# pse84 register map
Vendor: Infineon Technologies; Series: PSE84; File version: 1.0
CPU: CM33 r0p1, little endian, MPU, FPU, VTOR, 3 interrupt priority bits
Registers are 32-bit, read-write, reset 0x0 unless marked. A register's access mark holds for its fields unless they carry their own. Offsets are from the block's base; [hi:lo] are bit positions; lines under a group give offsets from that group; {n}, {i} and the like mark numbered series; 'fields as' and 'values as' point back to an identical list.

## GFXSS (part 2 of 5)
Base 0x44800000
0x1000 GFXSS_DC group — Display Controller.
  0x00 MXDC group — Platform IP standard configuration for DC.
    0x00 CTL — IP control.
      [31] ENABLED — IP enable bit. When disabled (value 0), the functional state of the DCNano core is reset and its clock input gated. Access to MMIO of the core results in an AHB error response. Note, that the effect of this bit is delayed (see STATUS.CORE_RST). The core must be idle (no outstanding or pending AXI transactions) before clearing this bit.
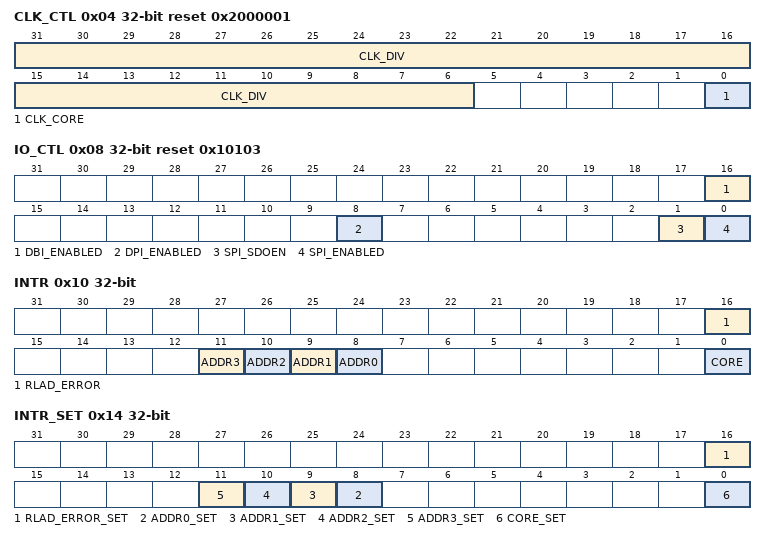
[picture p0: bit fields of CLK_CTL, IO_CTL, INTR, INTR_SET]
    0x04 CLK_CTL reset 0x2000001 — Clock control.
      [31:6] CLK_DIV — Setup of the fractional divider to generate clk_hf_div. In DPI mode the output is the pixel clock. In DBI Type C mode it's two times the serial clock. Format of programmed value is unsigned fix-point 10.16. It must not be set to a value smaller than 2.0 (= 0x020000). It can be set to 0, which results in no clock being generated. Change only while CTL.ENABLED is off.
      [0] CLK_CORE — Setup for DC core and AXI clock. Must only be set to 0 if clk_hf is not faster than 200 MHz. Change only while CTL.ENABLED is off.
        0=HF_DIV1 (Core clock is clk_hf.); 1=HF_DIV2 (Core clock is clk_hf divided by 2.)
    0x08 IO_CTL reset 0x10103 — IO enable control.
      [16] DBI_ENABLED — Enable control for IO cells in DBI Type A/B mode (1 = enabled). CTL.ENABLED must also be 1.
      [8] DPI_ENABLED — Enable control for IO cells in DPI mode (1 = enabled). CTL.ENABLED must also be 1.
      [1] SPI_SDOEN — Controls if the enable for spi_dout is separately controlled by the DCNano core with dbiTypecSdoEn signal (0 = yes, 1 = no). Field has no effect if SPI_ENABLED is 0.
      [0] SPI_ENABLED — Enable control for IO cells in DBI Type C mode (1 = enabled). CTL.ENABLED must also be 1.
    0x0C STATUS ro reset 0x1 — IP status.
      [0] CORE_RST — Reset state of the DCNano core (1 = in reset). This state is delayed to GFXSS_DC reset. After reset de-activation it has to be checked for value 0 before the core can be used. After activation it has to be checked for value 1 before turning off the external clk_hf source.
    0x10 INTR — Interrupt status.
      [16] RLAD_ERROR — The RLAD decoder has entered fail state (see RLAD_STATUS register). Writing a '1' to this field will reset the bit.
      [n+8] ADDR{n} (n=0..3) — Read access to INT_ADDR{n} completed. Writing a '1' to this field will reset the bit.
      [0] CORE — DCNano core has signalled an interrupt. Writing a '1' to this field will reset the bit. Interrupt status inside the core is not affected by this.
    0x14 INTR_SET — Interrupt set bits.
      [16] RLAD_ERROR_SET — Write this field with '1' to set corresponding INTR field (a write of '0' has no effect).
      [n+8] ADDR{n}_SET (n=0..3) — Write this field with '1' to set corresponding INTR field (a write of '0' has no effect).
      [0] CORE_SET — Write this field with '1' to set corresponding INTR field (a write of '0' has no effect).
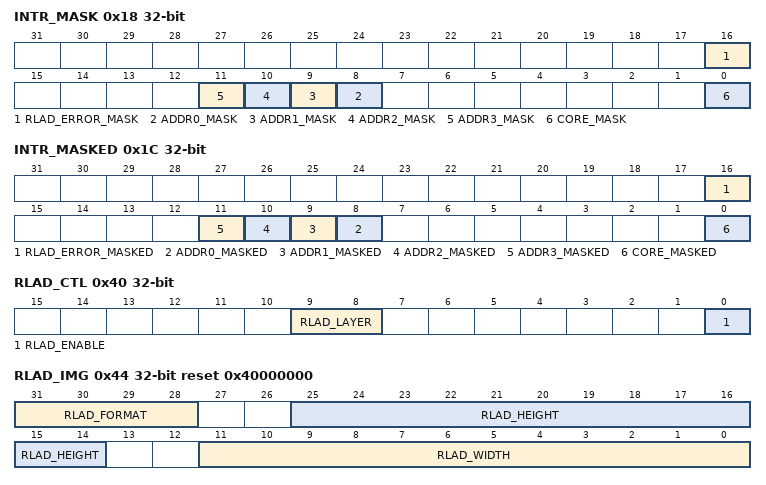
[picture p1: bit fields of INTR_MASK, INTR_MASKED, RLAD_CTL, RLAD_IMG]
    0x18 INTR_MASK — Interrupt mask bits.
      [16] RLAD_ERROR_MASK — Mask for corresponding field in INTR register.
      [n+8] ADDR{n}_MASK (n=0..3) — Mask for corresponding field in INTR register.
      [0] CORE_MASK — Mask for corresponding field in INTR register.
    0x1C INTR_MASKED ro — Interrupt masked bits.
      [16] RLAD_ERROR_MASKED — Logical AND of corresponding INTR and INTR_MASK fields.
      [n+8] ADDR{n}_MASKED (n=0..3) — Logical AND of corresponding INTR and INTR_MASK fields.
      [0] CORE_MASKED — Logical AND of corresponding INTR and INTR_MASK fields.
    0x20 ADDR0_INT — Address 0 for interrupt generation.
      [31:0] ADDR0_INT — A completed read access to this memory address will set INTR.ADDR0. The shadow values of all address fields are copied into the active configuration when a display frame has completed and GCREGPANELCONTROL_VALID was set before in DCNANO.
    {0x20+4k} ADDR{k}_INT (k=1..3) — Address {k} for interrupt generation.
      [31:0] ADDR{k}_INT — A completed read access to this memory address will set INTR.ADDR{k}.
    0x40 RLAD_CTL — Control options for the RLAD decoder.
      [9:8] RLAD_LAYER
      [0] RLAD_ENABLE — When set to 0, the RLAD decoder is disabled. It's clock tree is gated and the functional logic reset. All RLAD configuration fields, including this enable field, are shadowed. The shadow values are copied into the active configuration when a display frame has completed and GCREGPANELCONTROL_VALID was set before in DCNANO. Once the load of shadows has been initiated by setting the VALID flag, the RLAD configuration fields must not be changed again before the frame complete interrupt. Beside inconsistent setup for a display frame, this can lead to data corruption of the active configuration.
    0x44 RLAD_IMG reset 0x40000000 — Properties of the uncompressed image.
      [31:28] RLAD_FORMAT — Color format of the uncompressed image. The RLAD block converts the configured format after decompression to ARGB8888, which is the format the DC layer has to be configured for (in linear order and with component swizzle ARGB). Alpha value is set to 255 for RGB and GRAY formats.
        1=ARGB4444 (N/A); 2=ARGB1555 (N/A); 3=RGB565 (N/A); 4=ARGB8888 (N/A); 5=RGB888 (N/A); 6=RGB666 (N/A); 7=RGB444 (N/A); 8=GRAY8 (N/A); 9=GRAY6 (N/A); 10=GRAY4 (N/A)
      [25:14] RLAD_HEIGHT — Height of the image in number of lines minus one. The DC layer must be setup for the same height.
      [11:0] RLAD_WIDTH — Width of the image in number of pixels minus one. The DC layer must be setup for the same width.
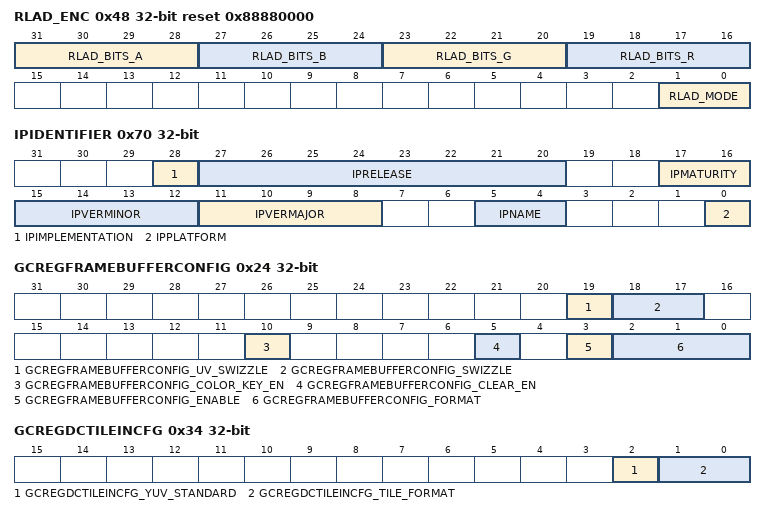
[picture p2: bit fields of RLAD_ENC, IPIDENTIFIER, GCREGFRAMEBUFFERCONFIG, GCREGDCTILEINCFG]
    0x48 RLAD_ENC reset 0x88880000 — Configuration of the encoder that compressed the image.
      [31:28] RLAD_BITS_A — Max number of alpha channel bits (used for RLAD modes only).
      [27:24] RLAD_BITS_B — Max number of blue channel bits (used for RLAD modes only).
      [23:20] RLAD_BITS_G — Max number of green channel bits (used for RLAD modes only).
      [19:16] RLAD_BITS_R — Max number of red channel bits (used for RLAD modes only).
      [1:0] RLAD_MODE — Encoding mode.
        0=RLAD (Run-Length Adaptive Dithering (lossy).); 1=RLAD_UNIFORM (RLAD with uniform package size (less efficient, but can force a consistent read bandwidth if needed).); 2=RLA (Run-Length Adaptive (lossless).); 3=RL (Standard Run-Length (lossless).)
    0x4C RLAD_BUF0 — Properties of the compressed image data buffer.
      [31:7] RLAD_ADDRESS — Base address of the encoded image buffer in multiple of 128 bytes. The DC layer must be configured to the same base address and with the smallest possible stride value (aligned to 128 bytes).
    0x50 RLAD_BUF1 — Properties of the compressed image data buffer.
      [28:0] RLAD_SIZE — Size of the the encoded image in number of 32-bit words minus one. The buffer must be readable to the subsequent 128 bytes boundary.
    0x54 RLAD_STATUS ro — RLAD decoder status.
      [2:0] RLAD_FAILED — The fail state is activated in case an error condition has been detected. This will also trigger the RLAD_ERROR interrupt. In that state the RLAD decoding process is stopped and the DC will only read null data. No more read accesses to the memory buffer are generated. The fail state is quit by disabling the DC via CTL.ENABLED.
        0=OFF (No fail state (= normal operation).); 1=AXI_ERROR (An AXI error response was received when reading compressed image data.); 2=BUF_TOO_SMALL (The RLAD_SIZE setting is inconsistent with the compressed image data (image decompression not complete when end of buffer was reached).); 3=BUF_TOO_LARGE (The RLAD_SIZE setting is inconsistent with the compressed image data (image decompression completed before end of buffer was reached).); 4=DC_INVALID_SIZE (The DC was reading the first pixel of a frame when it was not expected. This means an inconsistent setup of RLAD and DC configuration.); 5=DC_INVALID_FORMAT (The DC was reading data with an unexpected burst length. This means an invalid buffer format was configured.)
    0x70 IPIDENTIFIER ro reset not defined — GFXSS IP and desig release identification (with DC, GPU and MIPIDSI).
      [28] IPIMPLEMENTATION — Implementation type.
        0=RTL (Logic design for FPGA and ASIC synthesis.)
      [27:20] IPRELEASE — Release ID. This is independently set for each implementation type. The value starts with 0 and is increased for every new release of a an IP project, which is defined by IPName, IPVERMAJOR and IPVERMINOR.
      [17:16] IPMATURITY — IP Maturity Status with Chip Integration Cycle targets (CIC). This is independently set for each implementation type.
        0=NONE (Undefined.); 1=CPR (Implementation incomplete (for CIC Physical Readiness Review).); 2=CMR (Implementation complete (for CIC Mock Review).); 3=CFR (Verification complete (for CIC Final Handoff Review).)
      [15:12] IPVERMINOR — Minor IP Version Number.
      [11:8] IPVERMAJOR — Major IP Version Number.
      [5:4] IPNAME — Name of IP family.
        0=GFXSS (Graphics Subsystem with Display Controller for Low Power applications.)
      [0] IPPLATFORM — Name of SOC Platform.
        0=MXS22_S22 (MXS22 Base Variant.)
  0x800 DCNANO group — Host Interface Registers
    0x00 GCREGDCCHIPREV ro reset not defined — Chip Revision Register. Shows the revision for the chip in BCD. This register has no set reset value. It varies with the implementation. READ ONLY.
      [31:0] GCREGDCCHIPREV_REV — Revision. The reset value for this field is subject to change and may be ignored during test.
    0x04 GCREGDCCHIPDATE ro reset not defined — Chip Date Register. Shows the release date for the IP in YYYYMMDD (year, month. day) format. This register has no set reset value. It varies with the implementation. READ ONLY.
      [31:0] GCREGDCCHIPDATE_DATE — Date. The reset value for this field changes per release and may be ignored during test. You can read the accurate value from the RTL file because the actual value may be later than the document release time.
    0x08 GCREGDCCHIPPATCHREV ro reset not defined — Patch Revision Register. Patch revision level for the chip. READ ONLY.
      [31:0] GCREGDCCHIPPATCHREV_PATCH_REV — Patch revision. The reset value for this field changes per release and may be ignored during test. You can read the accurate value from the RTL file because the actual value may be later than the document release time.
    0x0C GCREGDCPRODUCTID ro reset 0x2080001 — Product Identification Register. READ ONLY.
      [31:0] GCREGDCPRODUCTID_PRODUCT_ID — Product ID. Bits 3:0 contain Product GRADE_LEVEL. 1 indicates level is Nano. Bits 23:4 contain Product NUM, product number. None for DCNano; 8000 for DC8000 Series. Bits 27:24 contain Product TYPE. 2 indicates Display Controller.
    0x24 GCREGFRAMEBUFFERCONFIG — Frame Buffer Configuration Register. Frame Buffer and Timing control. NOTE.. This register is double buffered.
      [19] GCREGFRAMEBUFFERCONFIG_UV_SWIZZLE — NOTE: This field is double buffered.
      [18:17] GCREGFRAMEBUFFERCONFIG_SWIZZLE — NOTE: This field is double buffered.
        0=ARGB ((none)); 1=RGBA ((none)); 2=ABGR ((none)); 3=BGRA ((none))
      [10] GCREGFRAMEBUFFERCONFIG_COLOR_KEY_EN — Enable or disable color key. NOTE: This field is double buffered.
        0=DISABLED ((none)); 1=ENABLED ((none))
      [5] GCREGFRAMEBUFFERCONFIG_CLEAR_EN — Enable or disable clear. NOTE: This field is double buffered.
        0=DISABLED ((none)); 1=ENABLED ((none))
      [3] GCREGFRAMEBUFFERCONFIG_ENABLE — Enable this layer or disable this layer. NOTE: This field is double buffered.
        0=DISABLED ((none)); 1=ENABLED ((none))
      [2:0] GCREGFRAMEBUFFERCONFIG_FORMAT — The format of the frame buffer. None means there is no frame buffer and the display controller will not produce any output. NOTE: This field is double buffered.
        0=NONE; 1=A4R4G4B4 ((none)); 2=A1R5G5B5 ((none)); 3=R5G6B5 ((none)); 4=A8R8G8B8 ((none))
    0x28 GCREGFRAMEBUFFERADDRESS — Frame Buffer Base Address Register. Starting address of the frame buffer. NOTE.. This register is double buffered.
      [31:0] GCREGFRAMEBUFFERADDRESS_ADDRESS — 32 bit address.
    0x2C GCREGFRAMEBUFFERSTRIDE — Frame Buffer Stride Register. Stride of the frame buffer in bytes. NOTE.. This register is double buffered.
      [16:0] GCREGFRAMEBUFFERSTRIDE_STRIDE — Number of bytes from start of one line to next line. NOTE: This field is double buffered.
    0x34 GCREGDCTILEINCFG — Tile Input Configuration Register. Tile input configuration. NOTE.. This register is double buffered.
      [2] GCREGDCTILEINCFG_YUV_STANDARD — YUV standard select. NOTE: This field is double buffered.
        0=BT601 ((none)); 1=BT709 ((none))
      [1:0] GCREGDCTILEINCFG_TILE_FORMAT — Tile input data format 0 means non-tile input. NOTE: This field is double buffered.
        0=NONE; 1=ARGB8888 ((none)); 2=YUY2 ((none)); 3=NV12 ((none))
    0x38 GCREGDCTILEUVFRAMEBUFFERADR — Frame Buffer Tiled UV Base Address Register. UV frame buffer address when tile input. NOTE.. This register is double buffered.
      [31:0] GCREGDCTILEUVFRAMEBUFFERADR_ADDRESS — UV frame buffer address when tile input NOTE: This field is double buffered.
    0x3C GCREGDCTILEUVFRAMEBUFFERSTR — Frame Buffer Tiled UV Stride Register. UV frame buffer stride when tile input NOTE.. This register is double buffered.
      [15:0] GCREGDCTILEUVFRAMEBUFFERSTR_STRIDE — UV frame buffer stride when tile input NOTE: This field is double buffered.
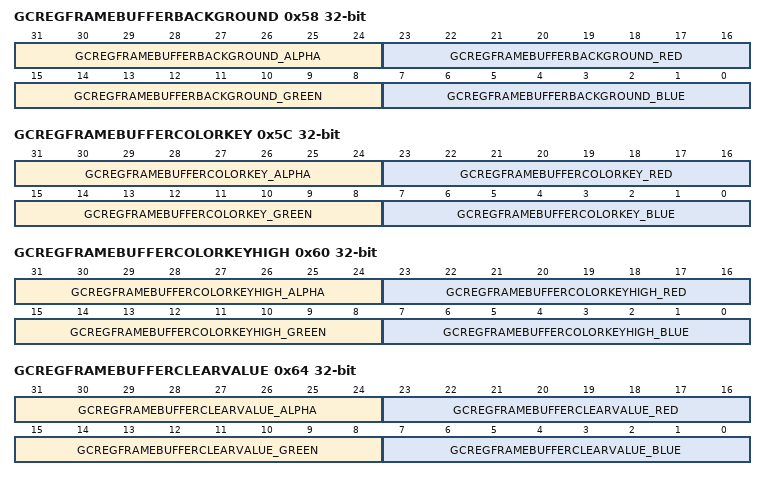
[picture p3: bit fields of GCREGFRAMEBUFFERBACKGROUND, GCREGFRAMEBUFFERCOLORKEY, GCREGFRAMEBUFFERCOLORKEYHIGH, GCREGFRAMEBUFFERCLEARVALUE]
    0x58 GCREGFRAMEBUFFERBACKGROUND — Framebuffer background color. NOTE.. This register is double buffered.
      [31:24] GCREGFRAMEBUFFERBACKGROUND_ALPHA — NOTE: This field is double buffered.
      [23:16] GCREGFRAMEBUFFERBACKGROUND_RED — NOTE: This field is double buffered.
      [15:8] GCREGFRAMEBUFFERBACKGROUND_GREEN — NOTE: This field is double buffered.
      [7:0] GCREGFRAMEBUFFERBACKGROUND_BLUE — NOTE: This field is double buffered.
    0x5C GCREGFRAMEBUFFERCOLORKEY — Framebuffer Color Key Start Address Register. Start of color key range of framebuffer. NOTE.. This register is double buffered.
      [31:24] GCREGFRAMEBUFFERCOLORKEY_ALPHA — 8 bit alpha value.
      [23:16] GCREGFRAMEBUFFERCOLORKEY_RED — 8 bit red color.
      [15:8] GCREGFRAMEBUFFERCOLORKEY_GREEN — 8 bit green color.
      [7:0] GCREGFRAMEBUFFERCOLORKEY_BLUE — 8 bit blue color.
    0x60 GCREGFRAMEBUFFERCOLORKEYHIGH — Framebuffer Color Key End Address Register. End of color key range of framebuffer. NOTE.. This register is double buffered.
      [31:24] GCREGFRAMEBUFFERCOLORKEYHIGH_ALPHA — 8 bit alpha value.
      [23:16] GCREGFRAMEBUFFERCOLORKEYHIGH_RED — 8 bit red color.
      [15:8] GCREGFRAMEBUFFERCOLORKEYHIGH_GREEN — 8 bit green color.
      [7:0] GCREGFRAMEBUFFERCOLORKEYHIGH_BLUE — 8 bit blue color.
    0x64 GCREGFRAMEBUFFERCLEARVALUE — Framebuffer Clear Value Register. Clear value used when dcregFrameBufferConfig.Clear is enabled, format is A8R8G8B8. NOTE.. This register is double buffered.
      [31:24] GCREGFRAMEBUFFERCLEARVALUE_ALPHA — 8 bit alpha value.
      [23:16] GCREGFRAMEBUFFERCLEARVALUE_RED — 8 bit red color.
      [15:8] GCREGFRAMEBUFFERCLEARVALUE_GREEN — 8 bit green color.
      [7:0] GCREGFRAMEBUFFERCLEARVALUE_BLUE — 8 bit blue color.
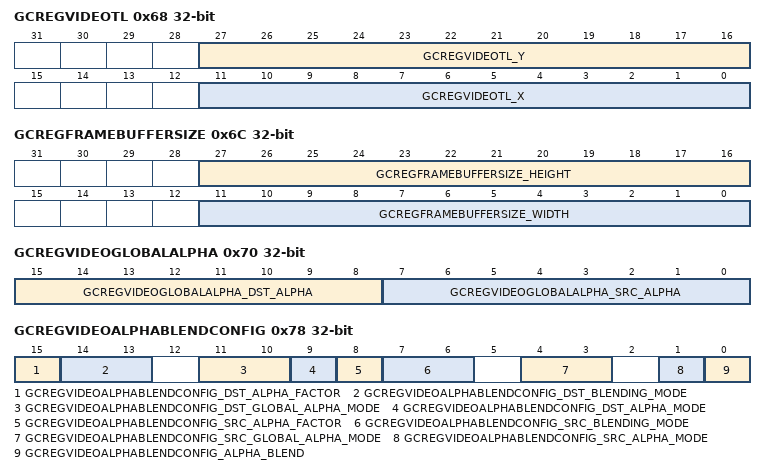
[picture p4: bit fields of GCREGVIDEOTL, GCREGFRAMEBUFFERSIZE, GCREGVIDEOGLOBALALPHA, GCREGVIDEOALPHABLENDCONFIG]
    0x68 GCREGVIDEOTL — Top left coordinate of panel pixel where the video should start. Be aware there is no panning inside the video. NOTE.. This register is double buffered.
      [27:16] GCREGVIDEOTL_Y — Top boundary of video window. NOTE: This field is double buffered.
      [11:0] GCREGVIDEOTL_X — Left boundary of video window. NOTE: This field is double buffered.
    0x6C GCREGFRAMEBUFFERSIZE — video size information. NOTE.. This register is double buffered.
      [27:16] GCREGFRAMEBUFFERSIZE_HEIGHT — video height. NOTE: This field is double buffered.
      [11:0] GCREGFRAMEBUFFERSIZE_WIDTH — video width. NOTE: This field is double buffered.
    0x70 GCREGVIDEOGLOBALALPHA — Global alpha for the video. NOTE.. This register is double buffered.
      [15:8] GCREGVIDEOGLOBALALPHA_DST_ALPHA — Destination alpha for video. NOTE: This field is double buffered.
      [7:0] GCREGVIDEOGLOBALALPHA_SRC_ALPHA — Source alpha for video. NOTE: This field is double buffered.
    0x74 GCREGBLENDSTACKORDER — Set the video, overlay0, overlay1 order for blend. The 1st is the lowest layer, the 2nd is the middle layer, the 3rd is the highest layer. NOTE.. This register is double buffered.
      [2:0] GCREGBLENDSTACKORDER_ORDER — NOTE: This field is double buffered.
        0=VIDEO_OVERLAY0_OVERLAY1 ((none)); 1=VIDEO_OVERLAY1_OVERLAY0 ((none)); 2=OVERLAY0_VIDEO_OVERLAY1 ((none)); 3=OVERLAY0_OVERLAY1_VIDEO ((none)); 4=OVERLAY1_VIDEO_OVERLAY0 ((none)); 5=OVERLAY1_OVERLAY0_VIDEO ((none))
    0x78 GCREGVIDEOALPHABLENDCONFIG — Alpha Blending Configuration Register. NOTE.. This register is double buffered.
      [15] GCREGVIDEOALPHABLENDCONFIG_DST_ALPHA_FACTOR — Destination blending factor is calculated from Dst alpha.
        0=DISABLED ((none)); 1=ENABLED ((none))
      [14:13] GCREGVIDEOALPHABLENDCONFIG_DST_BLENDING_MODE — Control the destination blending factor generation.
        0=ZERO ((none)); 1=ONE ((none)); 2=NORMAL ((none)); 3=INVERSED ((none))
      [11:10] GCREGVIDEOALPHABLENDCONFIG_DST_GLOBAL_ALPHA_MODE — Set destination global alpha mode.
        0=NORMAL ((none)); 1=GLOBAL ((none)); 2=SCALED ((none))
      [9] GCREGVIDEOALPHABLENDCONFIG_DST_ALPHA_MODE — Set destination alpha mode.
        0=NORMAL ((none)); 1=INVERSED ((none))
      [8] GCREGVIDEOALPHABLENDCONFIG_SRC_ALPHA_FACTOR — Src Blending factor is calculated from Src alpha.
        0=DISABLED ((none)); 1=ENABLED ((none))
      [7:6] GCREGVIDEOALPHABLENDCONFIG_SRC_BLENDING_MODE — Control the source blending factor generation.
        values as GCREGVIDEOALPHABLENDCONFIG_DST_BLENDING_MODE
      [4:3] GCREGVIDEOALPHABLENDCONFIG_SRC_GLOBAL_ALPHA_MODE — Set source global alpha mode.
        0=NORMAL ((none)); 1=GLOBAL ((none)); 2=SCALED ((none))
      [1] GCREGVIDEOALPHABLENDCONFIG_SRC_ALPHA_MODE — Set alpha source mode.
        0=NORMAL ((none)); 1=INVERSED ((none))
      [0] GCREGVIDEOALPHABLENDCONFIG_ALPHA_BLEND — Enable or disable alpha blending.
        0=DISABLED ((none)); 1=ENABLED ((none))
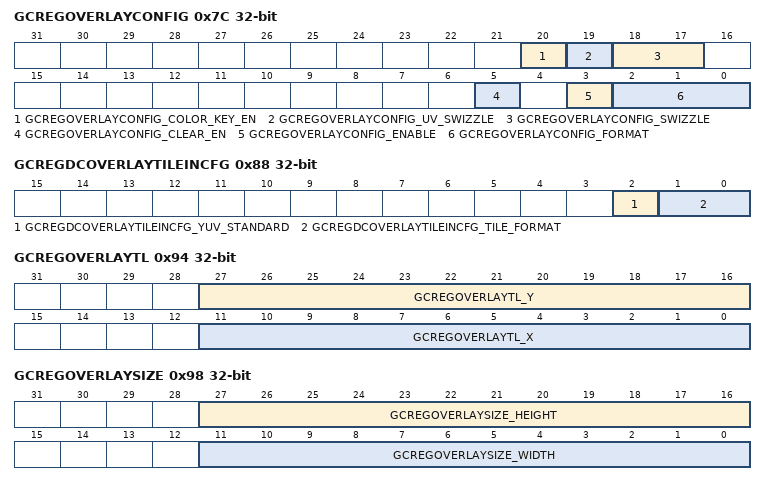
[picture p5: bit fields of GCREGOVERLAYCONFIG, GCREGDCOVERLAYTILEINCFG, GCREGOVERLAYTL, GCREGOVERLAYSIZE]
    0x7C GCREGOVERLAYCONFIG — Overlay Configuration Register. Overlay control. NOTE.. This register is double buffered.
      [20] GCREGOVERLAYCONFIG_COLOR_KEY_EN — Enable or disable color key. NOTE: This field is double buffered.
        0=DISABLED ((none)); 1=ENABLED ((none))
      [19] GCREGOVERLAYCONFIG_UV_SWIZZLE — NOTE: This field is double buffered.
      [18:17] GCREGOVERLAYCONFIG_SWIZZLE — NOTE: This field is double buffered.
        values as GFXSS_DC.DCNANO.GCREGFRAMEBUFFERCONFIG.GCREGFRAMEBUFFERCONFIG_SWIZZLE
      [5] GCREGOVERLAYCONFIG_CLEAR_EN — Enable or disable clear. NOTE: This field is double buffered.
        0=DISABLED ((none)); 1=ENABLED ((none))
      [3] GCREGOVERLAYCONFIG_ENABLE — Enable this overlay layer. NOTE: This field is double buffered.
        0=DISABLE ((none)); 1=ENABLE ((none))
      [2:0] GCREGOVERLAYCONFIG_FORMAT — The format of the overlay. None means there is no overlay. NOTE: This field is double buffered.
        values as GFXSS_DC.DCNANO.GCREGFRAMEBUFFERCONFIG.GCREGFRAMEBUFFERCONFIG_FORMAT
    0x80 GCREGOVERLAYADDRESS — Starting address of the overlay. NOTE.. This register is double buffered.
      [31:0] GCREGOVERLAYADDRESS_ADDRESS — 32 bit address.
    0x84 GCREGOVERLAYSTRIDE — Stride of the overlay in bytes. NOTE.. This register is double buffered.
      [16:0] GCREGOVERLAYSTRIDE_STRIDE — Number of bytes from start of one line to next line.
    0x88 GCREGDCOVERLAYTILEINCFG — Tile Input Configuration Register. Tile input configuration. NOTE.. This register is double buffered.
      [2] GCREGDCOVERLAYTILEINCFG_YUV_STANDARD — YUV standard select. NOTE: This field is double buffered.
        0=BT601 ((none)); 1=BT709 ((none))
      [1:0] GCREGDCOVERLAYTILEINCFG_TILE_FORMAT — Tile input data format 0 means non-tile input NOTE: This field is double buffered.
        values as GFXSS_DC.DCNANO.GCREGDCTILEINCFG.GCREGDCTILEINCFG_TILE_FORMAT
    0x8C GCREGDCTILEUVOVERLAYADR — Starting address of the overlay UV. NOTE.. This register is double buffered.
      [31:0] GCREGDCTILEUVOVERLAYADR_ADDRESS — 32 bit address.
    0x90 GCREGDCTILEUVOVERLAYSTR — Stride of the overlay UV in bytes. NOTE.. This register is double buffered.
      [15:0] GCREGDCTILEUVOVERLAYSTR_STRIDE — Number of bytes from start of one line to next line. NOTE: This field is double buffered.
    0x94 GCREGOVERLAYTL — Top left coordinate of panel pixel where the overlay should start. Be aware there is no panning inside the overlay. NOTE.. This register is double buffered.
      [27:16] GCREGOVERLAYTL_Y — Top boundary of overlay window.
      [11:0] GCREGOVERLAYTL_X — Left boundary of overlay window.
    0x98 GCREGOVERLAYSIZE — overlay size information. NOTE.. This register is double buffered.
      [27:16] GCREGOVERLAYSIZE_HEIGHT — overlay height.
      [11:0] GCREGOVERLAYSIZE_WIDTH — overlay width.
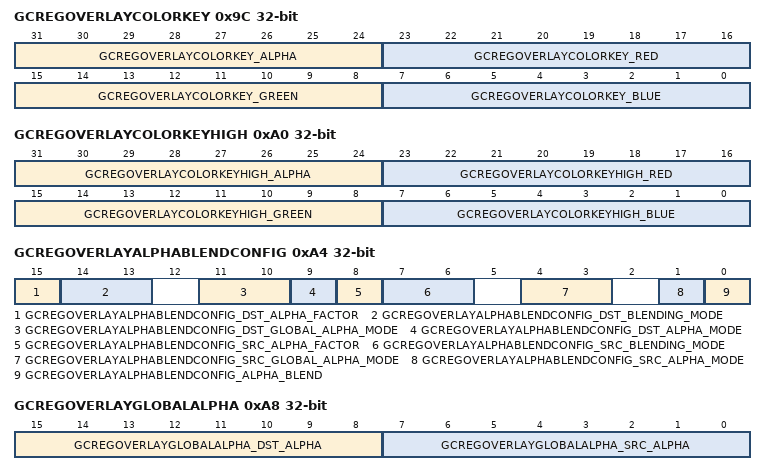
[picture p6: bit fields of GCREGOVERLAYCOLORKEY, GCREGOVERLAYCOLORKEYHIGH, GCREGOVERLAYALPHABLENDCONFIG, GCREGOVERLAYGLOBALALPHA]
    0x9C GCREGOVERLAYCOLORKEY — Overlay Color Key Start Address Register. Start of color key range for overlay. NOTE.. This register is double buffered.
      [31:24] GCREGOVERLAYCOLORKEY_ALPHA — 8 bit alpha value.
      [23:16] GCREGOVERLAYCOLORKEY_RED — 8 bit red color.
      [15:8] GCREGOVERLAYCOLORKEY_GREEN — 8 bit green color.
      [7:0] GCREGOVERLAYCOLORKEY_BLUE — 8 bit blue color.
    0xA0 GCREGOVERLAYCOLORKEYHIGH — Overlay Color Key End Address Register. End of color key range for overlay. NOTE.. This register is double buffered.
      [31:24] GCREGOVERLAYCOLORKEYHIGH_ALPHA — 8 bit alpha value.
      [23:16] GCREGOVERLAYCOLORKEYHIGH_RED — 8 bit red color.
      [15:8] GCREGOVERLAYCOLORKEYHIGH_GREEN — 8 bit green color.
      [7:0] GCREGOVERLAYCOLORKEYHIGH_BLUE — 8 bit blue color.
    0xA4 GCREGOVERLAYALPHABLENDCONFIG — Alpha Blending Configuration Register. NOTE.. This register is double buffered.
      [15] GCREGOVERLAYALPHABLENDCONFIG_DST_ALPHA_FACTOR — Destination blending factor is calculated from Dst alpha.
        0=DISABLED ((none)); 1=ENABLED ((none))
      [14:13] GCREGOVERLAYALPHABLENDCONFIG_DST_BLENDING_MODE — (none)
        values as GFXSS_DC.DCNANO.GCREGVIDEOALPHABLENDCONFIG.GCREGVIDEOALPHABLENDCONFIG_DST_BLENDING_MODE
      [11:10] GCREGOVERLAYALPHABLENDCONFIG_DST_GLOBAL_ALPHA_MODE — (none)
        0=NORMAL ((none)); 1=GLOBAL ((none)); 2=SCALED ((none))
      [9] GCREGOVERLAYALPHABLENDCONFIG_DST_ALPHA_MODE — (none)
        0=NORMAL ((none)); 1=INVERSED ((none))
      [8] GCREGOVERLAYALPHABLENDCONFIG_SRC_ALPHA_FACTOR — Src Blending factor is calculated from Src alpha.
        0=DISABLED ((none)); 1=ENABLED ((none))
      [7:6] GCREGOVERLAYALPHABLENDCONFIG_SRC_BLENDING_MODE — (none)
        values as GFXSS_DC.DCNANO.GCREGVIDEOALPHABLENDCONFIG.GCREGVIDEOALPHABLENDCONFIG_DST_BLENDING_MODE
      [4:3] GCREGOVERLAYALPHABLENDCONFIG_SRC_GLOBAL_ALPHA_MODE — (none)
        0=NORMAL ((none)); 1=GLOBAL ((none)); 2=SCALED ((none))
      [1] GCREGOVERLAYALPHABLENDCONFIG_SRC_ALPHA_MODE — (none)
        0=NORMAL ((none)); 1=INVERSED ((none))
      [0] GCREGOVERLAYALPHABLENDCONFIG_ALPHA_BLEND — (none)
        0=DISABLED ((none)); 1=ENABLED ((none))
    0xA8 GCREGOVERLAYGLOBALALPHA — Overlay global alpha value. NOTE.. This register is double buffered.
      [15:8] GCREGOVERLAYGLOBALALPHA_DST_ALPHA — (none)
      [7:0] GCREGOVERLAYGLOBALALPHA_SRC_ALPHA — (none)
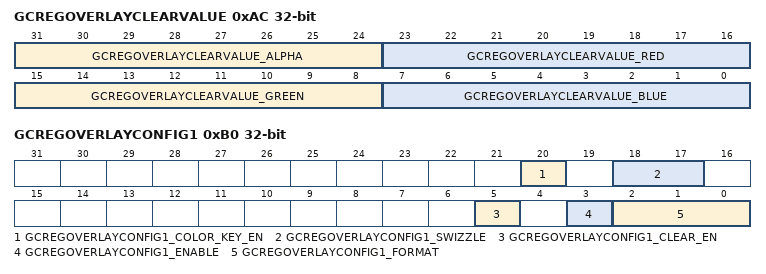
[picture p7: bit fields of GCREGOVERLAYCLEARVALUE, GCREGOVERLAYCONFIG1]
    0xAC GCREGOVERLAYCLEARVALUE — Overlay Clear Value Register. Clear value used when dcregOverlayConfig.Clear is enabled, Format is A8R8G8B8. NOTE.. This register is double buffered.
      [31:24] GCREGOVERLAYCLEARVALUE_ALPHA — 8 bit alpha value.
      [23:16] GCREGOVERLAYCLEARVALUE_RED — 8 bit red color.
      [15:8] GCREGOVERLAYCLEARVALUE_GREEN — 8 bit green color.
      [7:0] GCREGOVERLAYCLEARVALUE_BLUE — 8 bit blue color.
    0xB0 GCREGOVERLAYCONFIG1 — Overlay Configuration Register. Overlay control. NOTE.. This register is double buffered.
      [20] GCREGOVERLAYCONFIG1_COLOR_KEY_EN — Enable or disable color key. NOTE: This field is double buffered.
        0=DISABLED ((none)); 1=ENABLED ((none))
      [18:17] GCREGOVERLAYCONFIG1_SWIZZLE — NOTE: This field is double buffered.
        values as GFXSS_DC.DCNANO.GCREGFRAMEBUFFERCONFIG.GCREGFRAMEBUFFERCONFIG_SWIZZLE
      [5] GCREGOVERLAYCONFIG1_CLEAR_EN — Enable or disable clear. NOTE: This field is double buffered.
        0=DISABLED ((none)); 1=ENABLED ((none))
      [3] GCREGOVERLAYCONFIG1_ENABLE — Enable this overlay layer. NOTE: This field is double buffered.
        0=DISABLE ((none)); 1=ENABLE ((none))
      [2:0] GCREGOVERLAYCONFIG1_FORMAT — The format of the overlay. None means there is no overlay. NOTE: This field is double buffered.
        values as GFXSS_DC.DCNANO.GCREGFRAMEBUFFERCONFIG.GCREGFRAMEBUFFERCONFIG_FORMAT
    0xB4 GCREGOVERLAYADDRESS1 — Starting address of the overlay. NOTE.. This register is double buffered.
      [31:0] GCREGOVERLAYADDRESS1_ADDRESS — 32 bit address.
